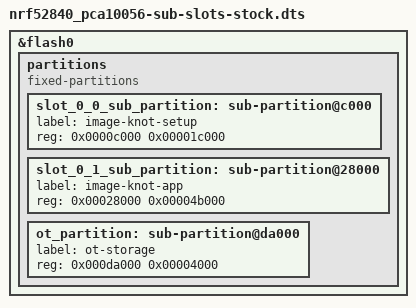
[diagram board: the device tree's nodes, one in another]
/*
 * Overlay file to permit using sub-slots with reduced space for setup app.
 */
&flash0 {
	/*
	 * For more information, see:
	 * http://docs.zephyrproject.org/latest/devices/dts/flash_partitions.html
	 */
	partitions {
		compatible = "fixed-partitions";
		#address-cells = <1>;
		#size-cells = <1>;

		/*
		 * Hack: Split image-0 into two sub-images
		 * (knot-setup and knot-app) so they can be refer to each other
		 * and recognized by MCUBOOT as a single image.
		 */

		slot_0_0_sub_partition: sub-partition@c000 {
			label = "image-knot-setup";
			reg = <0x0000c000 0x00001c000>;
		};

		slot_0_1_sub_partition: sub-partition@28000 {
			label = "image-knot-app";
			reg = <0x00028000 0x00004b000>;
		};

		/*
		 * Using first 4 pages of scratch partition for
		 * OpenThread storage.
		 * This is allowed as scratch area is used only
		 * during OTA update.
		 */
		ot_partition: sub-partition@da000 {
			label = "ot-storage";
			reg = <0x000da000 0x00004000>;
		};
	};
};
